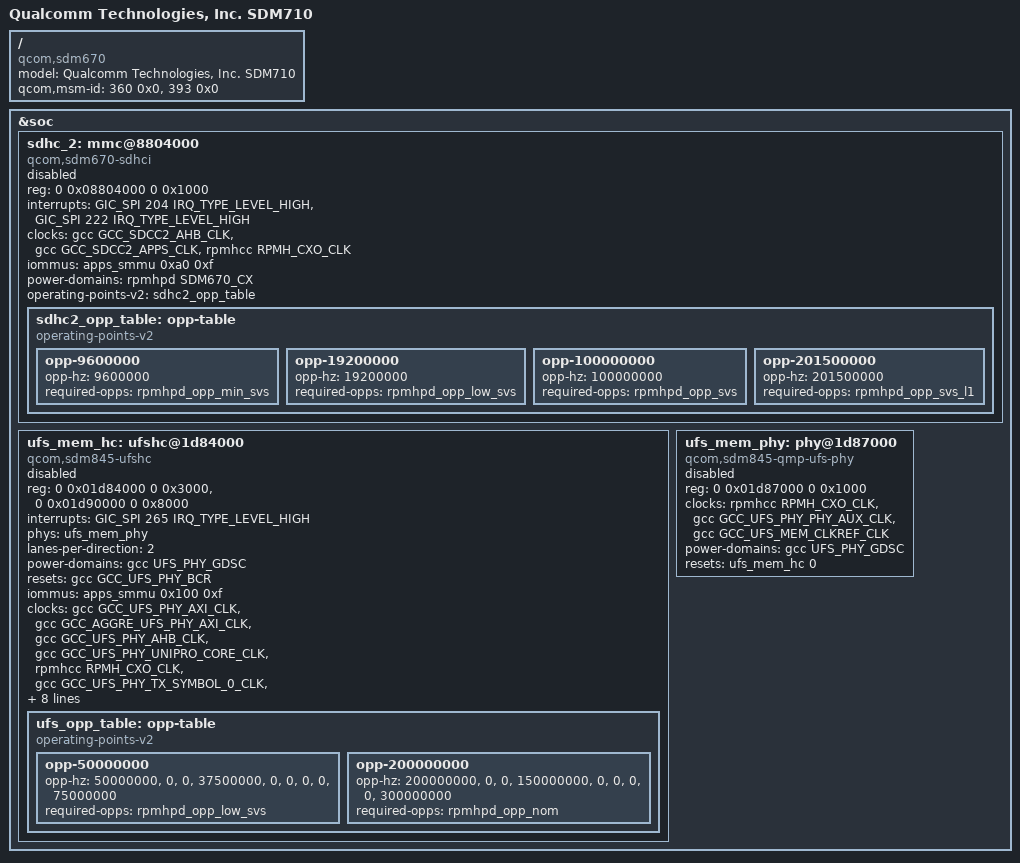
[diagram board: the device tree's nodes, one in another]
// SPDX-License-Identifier: GPL-2.0
/* 
 * SDM710 SoC device tree source
 *	
 * Copyright (c) 2018, The Linux Foundation. All rights reserved.
 * 
 */

#include "sdm670.dtsi"

/ {
	model = "Qualcomm Technologies, Inc. SDM710";
	compatible = "qcom,sdm670";
	qcom,msm-id =	<360 0x0>,
			<393 0x0>;
};

&soc {
	sdhc_2: mmc@8804000 {
			compatible = "qcom,sdm670-sdhci", "qcom,sdhci-msm-v5";
			reg = <0 0x08804000 0 0x1000>;

			interrupts = <GIC_SPI 204 IRQ_TYPE_LEVEL_HIGH>,
				     <GIC_SPI 222 IRQ_TYPE_LEVEL_HIGH>;
			interrupt-names = "hc_irq", "pwr_irq";

			clocks = <&gcc GCC_SDCC2_AHB_CLK>,
				 <&gcc GCC_SDCC2_APPS_CLK>,
				 <&rpmhcc RPMH_CXO_CLK>;
			clock-names = "iface", "core", "xo";
			iommus = <&apps_smmu 0xa0 0xf>;
			power-domains = <&rpmhpd SDM670_CX>;
			operating-points-v2 = <&sdhc2_opp_table>;

			status = "disabled";

			sdhc2_opp_table: opp-table {
				compatible = "operating-points-v2";

				opp-9600000 {
					opp-hz = /bits/ 64 <9600000>;
					required-opps = <&rpmhpd_opp_min_svs>;
				};

				opp-19200000 {
					opp-hz = /bits/ 64 <19200000>;
					required-opps = <&rpmhpd_opp_low_svs>;
				};

				opp-100000000 {
					opp-hz = /bits/ 64 <100000000>;
					required-opps = <&rpmhpd_opp_svs>;
				};

				opp-201500000 {
					opp-hz = /bits/ 64 <201500000>;
					required-opps = <&rpmhpd_opp_svs_l1>;
				};
			};
	};

	ufs_mem_hc: ufshc@1d84000 {
			compatible = "qcom,sdm845-ufshc", "qcom,ufshc",
				     "jedec,ufs-2.0";
			reg = <0 0x01d84000 0 0x3000>,
			      <0 0x01d90000 0 0x8000>;
			reg-names = "std", "ice";
			interrupts = <GIC_SPI 265 IRQ_TYPE_LEVEL_HIGH>;
			phys = <&ufs_mem_phy>;
			phy-names = "ufsphy";
			lanes-per-direction = <2>;
			power-domains = <&gcc UFS_PHY_GDSC>;
			#reset-cells = <1>;
			resets = <&gcc GCC_UFS_PHY_BCR>;
			reset-names = "rst";

			iommus = <&apps_smmu 0x100 0xf>;

			clock-names =
				"core_clk",
				"bus_aggr_clk",
				"iface_clk",
				"core_clk_unipro",
				"ref_clk",
				"tx_lane0_sync_clk",
				"rx_lane0_sync_clk",
				"rx_lane1_sync_clk",
				"ice_core_clk";
			clocks =
				<&gcc GCC_UFS_PHY_AXI_CLK>,
				<&gcc GCC_AGGRE_UFS_PHY_AXI_CLK>,
				<&gcc GCC_UFS_PHY_AHB_CLK>,
				<&gcc GCC_UFS_PHY_UNIPRO_CORE_CLK>,
				<&rpmhcc RPMH_CXO_CLK>,
				<&gcc GCC_UFS_PHY_TX_SYMBOL_0_CLK>,
				<&gcc GCC_UFS_PHY_RX_SYMBOL_0_CLK>,
				<&gcc GCC_UFS_PHY_RX_SYMBOL_1_CLK>,
				<&gcc GCC_UFS_PHY_ICE_CORE_CLK>;

			operating-points-v2 = <&ufs_opp_table>;

			interconnects = <&aggre1_noc MASTER_UFS_MEM 0 &mem_noc SLAVE_EBI_CH0 0>,
				<&gladiator_noc MASTER_AMPSS_M0 0 &config_noc SLAVE_UFS_MEM_CFG 0>;
			interconnect-names = "ufs-ddr", "cpu-ufs";

			status = "disabled";

			ufs_opp_table: opp-table {
				compatible = "operating-points-v2";

				opp-50000000 {
					opp-hz = /bits/ 64 <50000000>,
						 /bits/ 64 <0>,
						 /bits/ 64 <0>,
						 /bits/ 64 <37500000>,
						 /bits/ 64 <0>,
						 /bits/ 64 <0>,
						 /bits/ 64 <0>,
						 /bits/ 64 <0>,
						 /bits/ 64 <75000000>;
					required-opps = <&rpmhpd_opp_low_svs>;
				};

				opp-200000000 {
					opp-hz = /bits/ 64 <200000000>,
						 /bits/ 64 <0>,
						 /bits/ 64 <0>,
						 /bits/ 64 <150000000>,
						 /bits/ 64 <0>,
						 /bits/ 64 <0>,
						 /bits/ 64 <0>,
						 /bits/ 64 <0>,
						 /bits/ 64 <300000000>;
					required-opps = <&rpmhpd_opp_nom>;
				};
			};
		};

		ufs_mem_phy: phy@1d87000 {
			compatible = "qcom,sdm845-qmp-ufs-phy";
			reg = <0 0x01d87000 0 0x1000>;

			clocks = <&rpmhcc RPMH_CXO_CLK>,
				 <&gcc GCC_UFS_PHY_PHY_AUX_CLK>,
				 <&gcc GCC_UFS_MEM_CLKREF_CLK>;
			clock-names = "ref",
				      "ref_aux",
				      "qref";

			power-domains = <&gcc UFS_PHY_GDSC>;

			resets = <&ufs_mem_hc 0>;
			reset-names = "ufsphy";

			#phy-cells = <0>;
			status = "disabled";
		};
};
